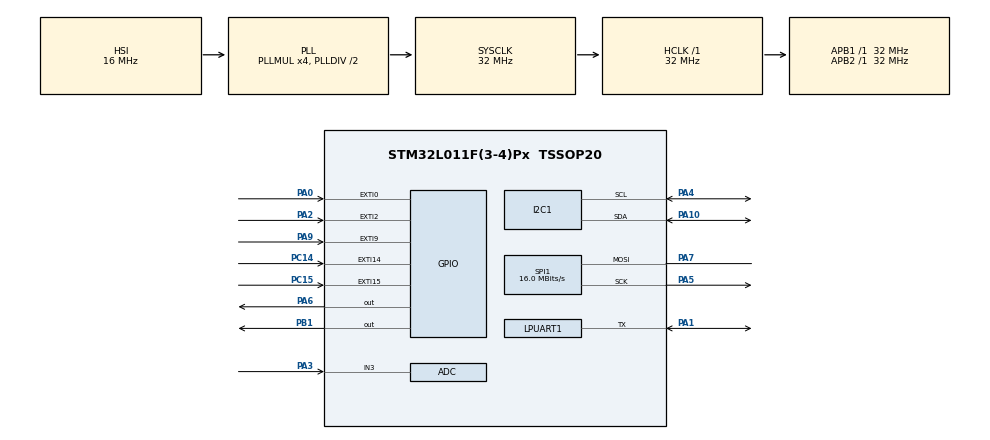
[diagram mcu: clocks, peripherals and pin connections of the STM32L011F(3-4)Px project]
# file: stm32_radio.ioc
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I2C1.Timing=0x00707CBB
Mcu.Family=STM32L0
Mcu.Name=STM32L011F(3-4)Px
Mcu.Package=TSSOP20
NVIC.EXTI0_1_IRQn=true\:0\:0\:false\:false\:true\:true
NVIC.EXTI2_3_IRQn=true\:0\:0\:false\:false\:true\:true
NVIC.EXTI4_15_IRQn=true\:0\:0\:false\:false\:true\:true
PA0-CK_IN.GPIO_ModeDefaultEXTI=GPIO_MODE_IT_FALLING
PA0-CK_IN.GPIO_PuPd=GPIO_PULLUP
PA0-CK_IN.Signal=GPXTI0
PA1.Mode=Half_duplex(single_wire_mode)
PA1.Signal=LPUART1_TX
PA10.Mode=I2C
PA10.Signal=I2C1_SDA
PA13.Mode=Serial_Wire
PA13.Signal=SYS_SWDIO
PA14.Mode=Serial_Wire
PA14.Signal=SYS_SWCLK
PA2.GPIO_ModeDefaultEXTI=GPIO_MODE_IT_FALLING
PA2.GPIO_PuPd=GPIO_PULLUP
PA2.Signal=GPXTI2
PA3.Mode=IN3
PA3.Signal=ADC_IN3
PA4.Mode=I2C
PA4.Signal=I2C1_SCL
PA5.Mode=Simplex_Bidirectional_Master
PA5.Signal=SPI1_SCK
PA6.Signal=GPIO_Output
PA7.Mode=Simplex_Bidirectional_Master
PA7.Signal=SPI1_MOSI
PA9.GPIO_ModeDefaultEXTI=GPIO_MODE_IT_FALLING
PA9.GPIO_PuPd=GPIO_PULLUP
PA9.Signal=GPXTI9
PB1.Signal=GPIO_Output
PC14-OSC32_IN.GPIO_ModeDefaultEXTI=GPIO_MODE_IT_FALLING
PC14-OSC32_IN.GPIO_PuPd=GPIO_PULLUP
PC14-OSC32_IN.Signal=GPXTI14
PC15-OSC32_OUT.GPIO_ModeDefaultEXTI=GPIO_MODE_IT_FALLING
PC15-OSC32_OUT.GPIO_PuPd=GPIO_PULLUP
PC15-OSC32_OUT.Signal=GPXTI15
ProjectManager.HeapSize=0x200
ProjectManager.StackSize=0x400
ProjectManager.TargetToolchain=SW4STM32
RCC.AHBFreq_Value=32000000
RCC.APB1Freq_Value=32000000
RCC.APB1TimFreq_Value=32000000
RCC.APB2Freq_Value=32000000
RCC.APB2TimFreq_Value=32000000
RCC.HCLKFreq_Value=32000000
RCC.HSE_VALUE=8000000
RCC.HSI16_VALUE=16000000
RCC.HSI_VALUE=16000000
RCC.LSE_VALUE=32768
RCC.MSI_VALUE=2097000
RCC.PLLMUL=RCC_PLLMUL_4
RCC.SYSCLKFreq_VALUE=32000000
RCC.SYSCLKSource=RCC_SYSCLKSOURCE_PLLCLK
RCC.VCOOutputFreq_Value=64000000
SPI1.CalculateBaudRate=16.0 MBits/s
SPI1.Direction=SPI_DIRECTION_1LINE
SPI1.Mode=SPI_MODE_MASTER
SPI1.VirtualType=VM_MASTER
board=stm32_radio

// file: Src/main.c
/**
  ******************************************************************************
  * File Name          : main.c
  * Description        : Main program body
  ******************************************************************************
  ** This notice applies to any and all portions of this file
  * that are not between comment pairs USER CODE BEGIN and
  * USER CODE END. Other portions of this file, whether
  * inserted by the user or by software development tools
  * are owned by their respective copyright owners.
  *
  * COPYRIGHT(c) 2018 STMicroelectronics
  *
  * Redistribution and use in source and binary forms, with or without modification,
  * are permitted provided that the following conditions are met:
  *   1. Redistributions of source code must retain the above copyright notice,
  *      this list of conditions and the following disclaimer.
  *   2. Redistributions in binary form must reproduce the above copyright notice,
  *      this list of conditions and the following disclaimer in the documentation
  *      and/or other materials provided with the distribution.
  *   3. Neither the name of STMicroelectronics nor the names of its contributors
  *      may be used to endorse or promote products derived from this software
  *      without specific prior written permission.
  *
  * THIS SOFTWARE IS PROVIDED BY THE COPYRIGHT HOLDERS AND CONTRIBUTORS "AS IS"
  * AND ANY EXPRESS OR IMPLIED WARRANTIES, INCLUDING, BUT NOT LIMITED TO, THE
  * IMPLIED WARRANTIES OF MERCHANTABILITY AND FITNESS FOR A PARTICULAR PURPOSE ARE
  * DISCLAIMED. IN NO EVENT SHALL THE COPYRIGHT HOLDER OR CONTRIBUTORS BE LIABLE
  * FOR ANY DIRECT, INDIRECT, INCIDENTAL, SPECIAL, EXEMPLARY, OR CONSEQUENTIAL
  * DAMAGES (INCLUDING, BUT NOT LIMITED TO, PROCUREMENT OF SUBSTITUTE GOODS OR
  * SERVICES; LOSS OF USE, DATA, OR PROFITS; OR BUSINESS INTERRUPTION) HOWEVER
  * CAUSED AND ON ANY THEORY OF LIABILITY, WHETHER IN CONTRACT, STRICT LIABILITY,
  * OR TORT (INCLUDING NEGLIGENCE OR OTHERWISE) ARISING IN ANY WAY OUT OF THE USE
  * OF THIS SOFTWARE, EVEN IF ADVISED OF THE POSSIBILITY OF SUCH DAMAGE.
  *
  ******************************************************************************
  */

#include "main.h"
#include "stm32l0xx_hal.h"

/* USER CODE BEGIN Includes */
#include "battery_measure.h"
#include <string.h>
/* USER CODE END Includes */

ADC_HandleTypeDef hadc;

I2C_HandleTypeDef hi2c1;

UART_HandleTypeDef hlpuart1;

SPI_HandleTypeDef hspi1;

/* USER CODE BEGIN PV */
/* Private variables ---------------------------------------------------------*/

/* USER CODE END PV */

void SystemClock_Config(void);
static void MX_GPIO_Init(void);
static void MX_ADC_Init(void);
static void MX_I2C1_Init(void);
static void MX_LPUART1_UART_Init(void);
static void MX_SPI1_Init(void);

/* USER CODE BEGIN PFP */
/* Private function prototypes -----------------------------------------------*/

/* USER CODE END PFP */

int main(void)
{

  /* MCU Configuration----------------------------------------------------------*/

  /* Reset of all peripherals, Initializes the Flash interface and the Systick. */
  HAL_Init();

  /* Configure the system clock */
  SystemClock_Config();

  /* Initialize all configured peripherals */
  MX_GPIO_Init();
  MX_ADC_Init();
  MX_I2C1_Init();
  MX_LPUART1_UART_Init();
  MX_SPI1_Init();

  /* USER CODE BEGIN 2 */

  const char test[] = "Hello!\n";
  HAL_UART_Transmit(&hlpuart1, (uint8_t*)test, sizeof(test)-1, 1000);

  char buf[30];
  float x = MeasureBattery();
  snprintf(buf, sizeof(buf), "Battery: %d milliVolt\n", (int)(x * 1000.0f));
  HAL_UART_Transmit(&hlpuart1, (uint8_t*)buf, strlen(buf), 1000);
  //HAL_UART_Transmit(&hlpuart1, (uint8_t*)&x, sizeof(x), 1000);

  /* USER CODE END 2 */

  /* Infinite loop */
  /* USER CODE BEGIN WHILE */
  while (1)
  {
	  //just do a low power sleep until something has occurred.
	  HAL_PWR_EnterSTOPMode(PWR_LOWPOWERREGULATOR_ON,PWR_STOPENTRY_WFI );
  /* USER CODE END WHILE */

  }

}

/** System Clock Configuration
*/
void SystemClock_Config(void)
{

  RCC_OscInitTypeDef RCC_OscInitStruct;
  RCC_ClkInitTypeDef RCC_ClkInitStruct;
  RCC_PeriphCLKInitTypeDef PeriphClkInit;

    /**Configure the main internal regulator output voltage
    */
  __HAL_PWR_VOLTAGESCALING_CONFIG(PWR_REGULATOR_VOLTAGE_SCALE1);

    /**Initializes the CPU, AHB and APB busses clocks
    */
  RCC_OscInitStruct.OscillatorType = RCC_OSCILLATORTYPE_HSI;
  RCC_OscInitStruct.HSIState = RCC_HSI_ON;
  RCC_OscInitStruct.HSICalibrationValue = 16;
  RCC_OscInitStruct.PLL.PLLState = RCC_PLL_ON;
  RCC_OscInitStruct.PLL.PLLSource = RCC_PLLSOURCE_HSI;
  RCC_OscInitStruct.PLL.PLLMUL = RCC_PLLMUL_4;
  RCC_OscInitStruct.PLL.PLLDIV = RCC_PLLDIV_2;
  if (HAL_RCC_OscConfig(&RCC_OscInitStruct) != HAL_OK)
  {
    _Error_Handler(__FILE__, __LINE__);
  }

    /**Initializes the CPU, AHB and APB busses clocks
    */
  RCC_ClkInitStruct.ClockType = RCC_CLOCKTYPE_HCLK|RCC_CLOCKTYPE_SYSCLK
                              |RCC_CLOCKTYPE_PCLK1|RCC_CLOCKTYPE_PCLK2;
  RCC_ClkInitStruct.SYSCLKSource = RCC_SYSCLKSOURCE_PLLCLK;
  RCC_ClkInitStruct.AHBCLKDivider = RCC_SYSCLK_DIV1;
  RCC_ClkInitStruct.APB1CLKDivider = RCC_HCLK_DIV1;
  RCC_ClkInitStruct.APB2CLKDivider = RCC_HCLK_DIV1;

  if (HAL_RCC_ClockConfig(&RCC_ClkInitStruct, FLASH_LATENCY_1) != HAL_OK)
  {
    _Error_Handler(__FILE__, __LINE__);
  }

  PeriphClkInit.PeriphClockSelection = RCC_PERIPHCLK_LPUART1|RCC_PERIPHCLK_I2C1;
  PeriphClkInit.Lpuart1ClockSelection = RCC_LPUART1CLKSOURCE_PCLK1;
  PeriphClkInit.I2c1ClockSelection = RCC_I2C1CLKSOURCE_PCLK1;
  if (HAL_RCCEx_PeriphCLKConfig(&PeriphClkInit) != HAL_OK)
  {
    _Error_Handler(__FILE__, __LINE__);
  }

    /**Configure the Systick interrupt time
    */
  HAL_SYSTICK_Config(HAL_RCC_GetHCLKFreq()/1000);

    /**Configure the Systick
    */
  HAL_SYSTICK_CLKSourceConfig(SYSTICK_CLKSOURCE_HCLK);

  /* SysTick_IRQn interrupt configuration */
  HAL_NVIC_SetPriority(SysTick_IRQn, 0, 0);
}

/* ADC init function */
static void MX_ADC_Init(void)
{

  ADC_ChannelConfTypeDef sConfig;

    /**Configure the global features of the ADC (Clock, Resolution, Data Alignment and number of conversion)
    */
  hadc.Instance = ADC1;
  hadc.Init.OversamplingMode = DISABLE;
  hadc.Init.ClockPrescaler = ADC_CLOCK_SYNC_PCLK_DIV2;
  hadc.Init.Resolution = ADC_RESOLUTION_12B;
  hadc.Init.SamplingTime = ADC_SAMPLETIME_1CYCLE_5;
  hadc.Init.ScanConvMode = ADC_SCAN_DIRECTION_FORWARD;
  hadc.Init.DataAlign = ADC_DATAALIGN_RIGHT;
  hadc.Init.ContinuousConvMode = DISABLE;
  hadc.Init.DiscontinuousConvMode = DISABLE;
  hadc.Init.ExternalTrigConvEdge = ADC_EXTERNALTRIGCONVEDGE_NONE;
  hadc.Init.ExternalTrigConv = ADC_SOFTWARE_START;
  hadc.Init.DMAContinuousRequests = DISABLE;
  hadc.Init.EOCSelection = ADC_EOC_SINGLE_CONV;
  hadc.Init.Overrun = ADC_OVR_DATA_PRESERVED;
  hadc.Init.LowPowerAutoWait = DISABLE;
  hadc.Init.LowPowerFrequencyMode = DISABLE;
  hadc.Init.LowPowerAutoPowerOff = DISABLE;
  if(HAL_ADCEx_EnableVREFINT()) {
	  Error_Handler();
  }
  if (HAL_ADC_Init(&hadc) != HAL_OK)
  {
    _Error_Handler(__FILE__, __LINE__);
  }

    /**Configure for the selected ADC regular channel to be converted.
    */
  //measure internal Voltage reference here instead of channel 3...
  //we didn't even need a pin to do that?!
  sConfig.Channel = ADC_CHANNEL_VREFINT; //ADC_CHANNEL_3;
  sConfig.Rank = ADC_RANK_CHANNEL_NUMBER;
  if (HAL_ADC_ConfigChannel(&hadc, &sConfig) != HAL_OK)
  {
    _Error_Handler(__FILE__, __LINE__);
  }

}

/* I2C1 init function */
static void MX_I2C1_Init(void)
{

  hi2c1.Instance = I2C1;
  hi2c1.Init.Timing = 0x00707CBB;
  hi2c1.Init.OwnAddress1 = 0;
  hi2c1.Init.AddressingMode = I2C_ADDRESSINGMODE_7BIT;
  hi2c1.Init.DualAddressMode = I2C_DUALADDRESS_DISABLE;
  hi2c1.Init.OwnAddress2 = 0;
  hi2c1.Init.OwnAddress2Masks = I2C_OA2_NOMASK;
  hi2c1.Init.GeneralCallMode = I2C_GENERALCALL_DISABLE;
  hi2c1.Init.NoStretchMode = I2C_NOSTRETCH_DISABLE;
  if (HAL_I2C_Init(&hi2c1) != HAL_OK)
  {
    _Error_Handler(__FILE__, __LINE__);
  }

    /**Configure Analogue filter
    */
  if (HAL_I2CEx_ConfigAnalogFilter(&hi2c1, I2C_ANALOGFILTER_ENABLE) != HAL_OK)
  {
    _Error_Handler(__FILE__, __LINE__);
  }

    /**Configure Digital filter
    */
  if (HAL_I2CEx_ConfigDigitalFilter(&hi2c1, 0) != HAL_OK)
  {
    _Error_Handler(__FILE__, __LINE__);
  }

}

/* LPUART1 init function */
static void MX_LPUART1_UART_Init(void)
{

  hlpuart1.Instance = LPUART1;
  hlpuart1.Init.BaudRate = 209700;
  hlpuart1.Init.WordLength = UART_WORDLENGTH_7B;
  hlpuart1.Init.StopBits = UART_STOPBITS_1;
  hlpuart1.Init.Parity = UART_PARITY_NONE;
  hlpuart1.Init.Mode = UART_MODE_TX_RX;
  hlpuart1.Init.HwFlowCtl = UART_HWCONTROL_NONE;
  hlpuart1.Init.OneBitSampling = UART_ONE_BIT_SAMPLE_DISABLE;
  hlpuart1.AdvancedInit.AdvFeatureInit = UART_ADVFEATURE_NO_INIT;
  if (HAL_HalfDuplex_Init(&hlpuart1) != HAL_OK)
  {
    _Error_Handler(__FILE__, __LINE__);
  }

}

/* SPI1 init function */
static void MX_SPI1_Init(void)
{

  /* SPI1 parameter configuration*/
  hspi1.Instance = SPI1;
  hspi1.Init.Mode = SPI_MODE_MASTER;
  hspi1.Init.Direction = SPI_DIRECTION_1LINE;
  hspi1.Init.DataSize = SPI_DATASIZE_8BIT;
  hspi1.Init.CLKPolarity = SPI_POLARITY_LOW;
  hspi1.Init.CLKPhase = SPI_PHASE_1EDGE;
  hspi1.Init.NSS = SPI_NSS_SOFT;
  hspi1.Init.BaudRatePrescaler = SPI_BAUDRATEPRESCALER_2;
  hspi1.Init.FirstBit = SPI_FIRSTBIT_MSB;
  hspi1.Init.TIMode = SPI_TIMODE_DISABLE;
  hspi1.Init.CRCCalculation = SPI_CRCCALCULATION_DISABLE;
  hspi1.Init.CRCPolynomial = 7;
  if (HAL_SPI_Init(&hspi1) != HAL_OK)
  {
    _Error_Handler(__FILE__, __LINE__);
  }

}

/** Configure pins as
        * Analog
        * Input
        * Output
        * EVENT_OUT
        * EXTI
*/
static void MX_GPIO_Init(void)
{

  GPIO_InitTypeDef GPIO_InitStruct;

  /* GPIO Ports Clock Enable */
  __HAL_RCC_GPIOC_CLK_ENABLE();
  __HAL_RCC_GPIOA_CLK_ENABLE();
  __HAL_RCC_GPIOB_CLK_ENABLE();

  /*Configure GPIO pin Output Level */
  HAL_GPIO_WritePin(GPIOA, GPIO_PIN_6, GPIO_PIN_RESET);

  /*Configure GPIO pin Output Level */
  HAL_GPIO_WritePin(GPIOB, GPIO_PIN_1, GPIO_PIN_RESET);

  /*Configure GPIO pins : PC14 PC15 */
  GPIO_InitStruct.Pin = GPIO_PIN_14|GPIO_PIN_15;
  GPIO_InitStruct.Mode = GPIO_MODE_IT_FALLING;
  GPIO_InitStruct.Pull = GPIO_PULLUP;
  HAL_GPIO_Init(GPIOC, &GPIO_InitStruct);

  /*Configure GPIO pins : PA0 PA2 PA9 */
  GPIO_InitStruct.Pin = GPIO_PIN_0|GPIO_PIN_2|GPIO_PIN_9;
  GPIO_InitStruct.Mode = GPIO_MODE_IT_FALLING;
  GPIO_InitStruct.Pull = GPIO_PULLUP;
  HAL_GPIO_Init(GPIOA, &GPIO_InitStruct);

  /*Configure GPIO pin : PA6 */
  GPIO_InitStruct.Pin = GPIO_PIN_6;
  GPIO_InitStruct.Mode = GPIO_MODE_OUTPUT_PP;
  GPIO_InitStruct.Pull = GPIO_NOPULL;
  GPIO_InitStruct.Speed = GPIO_SPEED_FREQ_LOW;
  HAL_GPIO_Init(GPIOA, &GPIO_InitStruct);

  /*Configure GPIO pin : PB1 */
  GPIO_InitStruct.Pin = GPIO_PIN_1;
  GPIO_InitStruct.Mode = GPIO_MODE_OUTPUT_PP;
  GPIO_InitStruct.Pull = GPIO_NOPULL;
  GPIO_InitStruct.Speed = GPIO_SPEED_FREQ_LOW;
  HAL_GPIO_Init(GPIOB, &GPIO_InitStruct);

  /* EXTI interrupt init*/
  HAL_NVIC_SetPriority(EXTI0_1_IRQn, 0, 0);
  HAL_NVIC_EnableIRQ(EXTI0_1_IRQn);

  HAL_NVIC_SetPriority(EXTI2_3_IRQn, 0, 0);
  HAL_NVIC_EnableIRQ(EXTI2_3_IRQn);

  HAL_NVIC_SetPriority(EXTI4_15_IRQn, 0, 0);
  HAL_NVIC_EnableIRQ(EXTI4_15_IRQn);

}

void _Error_Handler(char * file, int line)
{
  while(1)
  {
  }
}

/************************ (C) COPYRIGHT STMicroelectronics *****END OF FILE****/
